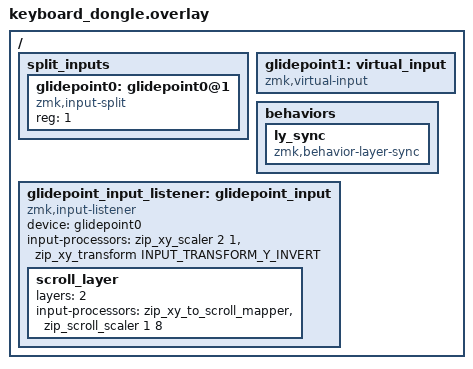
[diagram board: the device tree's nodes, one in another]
/* Central dongle overlay for nrf52840_mdk_usb_dongle */

#include "keyboard_dongle.dtsi"
#include <input/processors.dtsi>
#include <dt-bindings/zmk/input_transform.h>

/ {
    /* Native ZMK split input support - central side receives input from peripherals */
    split_inputs {
        #address-cells = <1>;
        #size-cells = <0>;

        /* Split device for right peripheral glidepoint (reg 1) - keymap expects glidepoint0 */
        glidepoint0: glidepoint0@1 {
            compatible = "zmk,input-split";
            reg = <1>;
        };
    };

    /* Virtual input device for keymap compatibility - left side has no physical input */
    glidepoint1: virtual_input {
        compatible = "zmk,virtual-input";
    };

    behaviors {
        ly_sync: ly_sync {
            compatible = "zmk,behavior-layer-sync";
            #binding-cells = <0>;
        };
    };

    /* Input listener for received pointer events */
    glidepoint_input_listener: glidepoint_input {
        compatible = "zmk,input-listener";
        device = <&glidepoint0>;
        /* 2x scaling with Y-invert for normal pointer movement */
        input-processors = <&zip_xy_scaler 2 1>, <&zip_xy_transform INPUT_TRANSFORM_Y_INVERT>;
        
        /* Layer-specific override: convert to scroll on SYM layer (layer 2) */
        scroll_layer {
            layers = <2>;
            input-processors = <&zip_xy_to_scroll_mapper>, <&zip_scroll_scaler 1 8>;
        };
    };
};
